# WKUP_CTRL_MMR0_CFG0 register map
Vendor: Texas Instruments
Registers are 32-bit, read-write, reset 0x0 unless marked. A register's access mark holds for its fields unless they carry their own. Offsets are as the file gives them; [hi:lo] are bit positions; {n}, {i} and the like mark numbered series; 'fields as' and 'values as' point back to an identical list.

## WKUP_CTRL_MMR0_CFG0 (part 3 of 11)
{0x6140+4i} CFG0_WKUP_SPARE_STAT{i}_PROXY ro (i=0..3)
  [31:0] WKUP_SPARE_STAT{i}_SPARE_IN_PROXY — Read-only bits. Reset by PORz only. Do not optimize away inputs
{0x6140+4i} CFG0_WKUP_SPARE_STAT{i}_PROXY ro (i=4..7)
  [31:0] WKUP_SPARE_STAT{i}_SPARE_IN_PROXY — Read-only bits. Reset by any reset. Do not optimize away inputs
{0x7100+4i} CFG0_CLAIMREG_P1_R{i} (i=0..2)
  [31:0] CLAIMREG_P1_R{i} — Claim bits for Partition 1
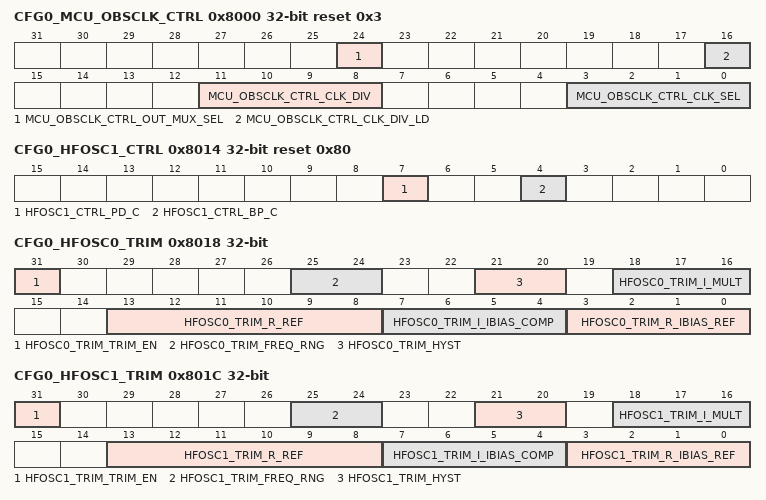
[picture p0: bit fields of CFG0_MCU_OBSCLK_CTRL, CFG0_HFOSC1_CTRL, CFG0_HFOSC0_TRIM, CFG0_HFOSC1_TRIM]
0x8000 CFG0_MCU_OBSCLK_CTRL reset 0x3
  [24] MCU_OBSCLK_CTRL_OUT_MUX_SEL — MCU_OBSCLK pin output mux selection. Note, when HFOSC0_CLK is selected (1'b1) the MCU_OBSCLK_CTRL_clk_sel field must be programmed to 4'b0001. 1'b0 - The output of the MCU_OBSCLK output divider is output on the pin 1'b1 - HFOSC0_CLK is output on the pin
  [16] MCU_OBSCLK_CTRL_CLK_DIV_LD — Load the output divider value Writing 1 to this bit will generate a load pulse to load the OBSCLK divider value. This bit can be cleared but must not be set in the same write cycle in which the clk_div value is changed.
  [11:8] MCU_OBSCLK_CTRL_CLK_DIV — MCU_OBSCLK pin clock selection output divider Output clock is divided by clk_div+1
  [3:0] MCU_OBSCLK_CTRL_CLK_SEL — MCU_OBSCLK pin clock selection Field values (others are reserved): 4'b0000 - CLK_12M_RC 4'b0001 - '0' 4'b0010 - MCU_PLL0_HSDIV0_CLKOUT 4'b0011 - MCU_PLLCTL_OBSCLK 4'b0100 - MCU_PLL1_HSDIV1_CLKOUT 4'b0101 - MCU_PLL1_HSDIV2_CLKOUT 4'b0110 - MCU_PLL1_HSDIV3_CLKOUT 4'b0111 - MCU_PLL1_HSDIV4_CLKOUT 4'b1000 - MCU_PLL2_HSDIV0_CLKOUT 4'b1001 - CLK_32K 4'b1010 - MCU_PLL2_HSDIV1_CLKOUT 4'b1011 - MCU_PLL2_HSDIV2_CLKOUT 4'b1100 - MCU_PLL2_HSDIV3_CLKOUT 4'b1101 - MCU_PLL2_HSDIV4_CLKOUT 4'b1110 - HFOSC0_CLKOUT 4'b1111 - LFXOSC_CLKOUT
0x8014 CFG0_HFOSC1_CTRL reset 0x80
  [7] HFOSC1_CTRL_PD_C — Oscillator powerdown control. When set, oscillator is disabled. Oscillator output is tristated if bp_c=0
  [4] HFOSC1_CTRL_BP_C — Oscillator bypass control. When set oscillator is in bypass mode
0x8018 CFG0_HFOSC0_TRIM
  [31] HFOSC0_TRIM_TRIM_EN — Apply MMR values to OSC trim inputs instead of tie-offs
  [25:24] HFOSC0_TRIM_FREQ_RNG — Sets the frequency range of operation based on: I(MIRRBIAS) = I(AGC) + 4x I(BIAS) (I(BIAS) : Bias current to AMP_AGC Block, I(AGC) : Current from AGC Loop and mirrored)
  [21:20] HFOSC0_TRIM_HYST — Sets comparator hysteresis
  [18:16] HFOSC0_TRIM_I_MULT — AGC AMP current multiplication gain I(MIRRBIAS) = I(AGC) + 4x I(BIAS) (I(BIAS) : Bias current to AMP_AGC Block, I(AGC) : Current from AGC Loop and mirrored)
  [13:8] HFOSC0_TRIM_R_REF — Sets the AMP AGC bias current r_ref(5:3) are not used.
  [7:4] HFOSC0_TRIM_I_IBIAS_COMP — Sets the COMP bias current x = 1 uA
  [3:0] HFOSC0_TRIM_R_IBIAS_REF — Sets the base IBIAS reference
0x801C CFG0_HFOSC1_TRIM
  [31] HFOSC1_TRIM_TRIM_EN — Apply MMR values to OSC trim inputs instead of tie-offs
  [25:24] HFOSC1_TRIM_FREQ_RNG — Sets the frequency range of operation based on: I(MIRRBIAS) = I(AGC) + 4x I(BIAS) (I(BIAS) : Bias current to AMP_AGC Block, I(AGC) : Current from AGC Loop and mirrored)
  [21:20] HFOSC1_TRIM_HYST — Sets comparator hysteresis
  [18:16] HFOSC1_TRIM_I_MULT — AGC AMP current multiplication gain I(MIRRBIAS) = I(AGC) + 4x I(BIAS) (I(BIAS) : Bias current to AMP_AGC Block, I(AGC) : Current from AGC Loop and mirrored)
  [13:8] HFOSC1_TRIM_R_REF — Sets the AMP AGC bias current r_ref(5:3) are not used.
  [7:4] HFOSC1_TRIM_I_IBIAS_COMP — Sets the COMP bias current x = 1 uA
  [3:0] HFOSC1_TRIM_R_IBIAS_REF — Sets the base IBIAS reference
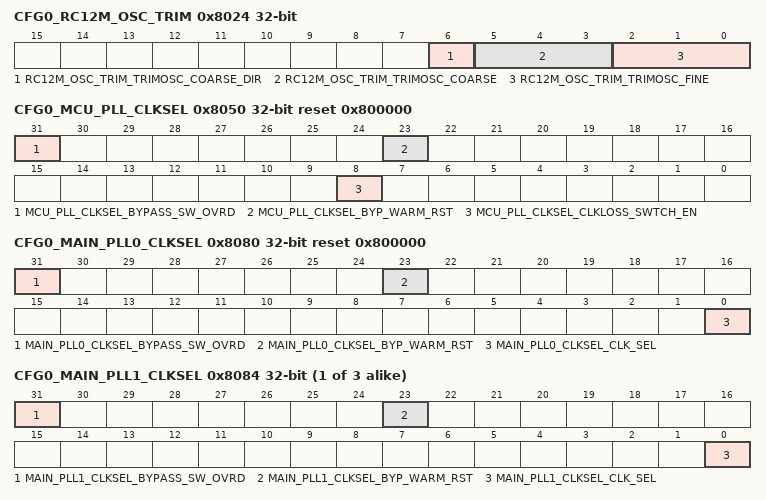
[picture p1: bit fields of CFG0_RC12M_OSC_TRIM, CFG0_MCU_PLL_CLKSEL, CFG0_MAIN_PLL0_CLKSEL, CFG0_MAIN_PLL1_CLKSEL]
0x8024 CFG0_RC12M_OSC_TRIM
  [6] RC12M_OSC_TRIM_TRIMOSC_COARSE_DIR — Coarse adjustment direction. If output is greater than 12.5 0 - Coarse adjustment decreases frequency 1 - Coarse adjustment increases frequency
  [5:3] RC12M_OSC_TRIM_TRIMOSC_COARSE — Coarse adjustment. Frequency is decreased or increased by 1.25 MHz per value based on the trimosc_coarse_dir value.
  [2:0] RC12M_OSC_TRIM_TRIMOSC_FINE — Fine adjustment. Decreases the frequency by 250 KHz per value.
0x8050 CFG0_MCU_PLL_CLKSEL reset 0x800000
  [31] MCU_PLL_CLKSEL_BYPASS_SW_OVRD — PLL Bypass warm reset software override When set, enables software control of exit from bypass mode on a mcu_reset_z for MCU PLL[2:0]. This bit must not be set until after the corresponding byp_warm_rst bit has been cleared or the PLL will immediately enter bypass mode.
  [23] MCU_PLL_CLKSEL_BYP_WARM_RST — PLL bypass mode after warm reset. This bit is only valid when bypass_sw_ovrd is set to 1'b1 to enable bypass software override. This bit is set (1'b1) when an MCU warm reset occurs and will keep MCU PLL[2:0] in bypass mode after reset exit until cleared by software. 1'b0 = Exit bypass mode (based on MCU PLL[2:0]_CTRL_bypass_en bit value) 1'b1 = Maintain bypass mode.
  [8] MCU_PLL_CLKSEL_CLKLOSS_SWTCH_EN — When set, enables automatic switching of MCU PLL[2:0] clock source to CLK_12M_RC if HFOSC0 clock loss is detected
0x8060 CFG0_WKUP_PER_CLKSEL
  [0] WKUP_PER_CLKSEL_MCUPLL_BYPASS — Select the main oscillator clock rather than the PLL generated clock as the functional clock (PLL BYPASS mode). 1'b0: WKUP_I2C functional clock is MCU_PLL1_HSDIV3_CLKOUT WKUP_USART functional clock is MCU_PLL1_HSDIV3_CLKOUT or MAIN_PLL_HSDIV5_CLKOUT as selected by WKUP_USART_CLKSEL.clk_sel 1'b1: WKUP_I2C functional clock is HFOSC0_CLKOUT WKUP_USART functional clock is HFOSC0_CLKOUT
0x8064 CFG0_WKUP_USART_CLKSEL
  [0] WKUP_USART_CLKSEL_CLK_SEL — WKUP_USART0 FCLK selection 1'b0 - MCU_PLL1_HSDIV3_CLKOUT 1'b1 - MAIN_PLL_HSDIV5_CLKOUT
0x8070 CFG0_WKUP_GPIO_CLKSEL
  [1:0] WKUP_GPIO_CLKSEL_WAKE_CLK_SEL — WKUP_GPIO clock selection. Must be set to MCU_SYSCLK0/4 whenever WKUP_GPIO VBUS interface is enabled. Other clock source may be selected as a wake up clock for DeepSleep modes after WKUP_GPIO is gated off through LPSC. Field values (others are reserved): 2'b00 - MCU_SYSCLK0 / 8 2'b01 - MCU_SYSCLK0 / 8 2'b10 - CLK_32K 2'b11 - CLK_12M_RC
0x8080 CFG0_MAIN_PLL0_CLKSEL reset 0x800000
  [31] MAIN_PLL0_CLKSEL_BYPASS_SW_OVRD — PLL Bypass warm reset software override When set, enables software control of exit from bypass mode on a main_reset_z for MAIN PLL0. This bit must not be set until after the corresponding byp_warm_rst bit has been cleared or the PLL will immediately enter bypass mode.
  [23] MAIN_PLL0_CLKSEL_BYP_WARM_RST — PLL bypass mode after warm reset. This bit is only valid when bypass_sw_ovrd is set to 1'b1 to enable bypass software override. This bit is set (1'b1) when a MAIN warm reset occurs and will keep MAIN PLL0 in bypass mode after reset exit until cleared by software. 1'b0 = Exit bypass mode (based on MAIN PLL0_CTRL_bypass_en bit value) 1'b1 = Maintain bypass mode.
  [0] MAIN_PLL0_CLKSEL_CLK_SEL — Selects the clock source for MAIN PLL0 1'b0 - Use HFOSC0_CLKOUT 1'b1 - Use HFOSC1_CLKOUT
{0x8080+4i} CFG0_MAIN_PLL{i}_CLKSEL (i=1..3)
  [31] MAIN_PLL{i}_CLKSEL_BYPASS_SW_OVRD — PLL Bypass warm reset software override This bit has no effect on PLL operation as MAIN PLL{i} is reset isolated and exit from bypass mode (in the case of a Thermal reset) is always hardware controlled.
  [23] MAIN_PLL{i}_CLKSEL_BYP_WARM_RST — PLL bypass mode after warm reset. This bit is cleared to 1'b0 when a MAIN warm reset occurs which will cause MAIN PLL{i} to exit bypass mode after reset exit. Setting this bit will have no effect on PLL behavior. Because MAIN PLL{i} is warm reset insensitive, bypass mode will only be entered (and exited) in the case of a Thermal reset event.
  [0] MAIN_PLL{i}_CLKSEL_CLK_SEL — Selects the clock source for MAIN PLL{i} 1'b0 - Use HFOSC0_CLKOUT 1'b1 - Use HFOSC1_CLKOUT
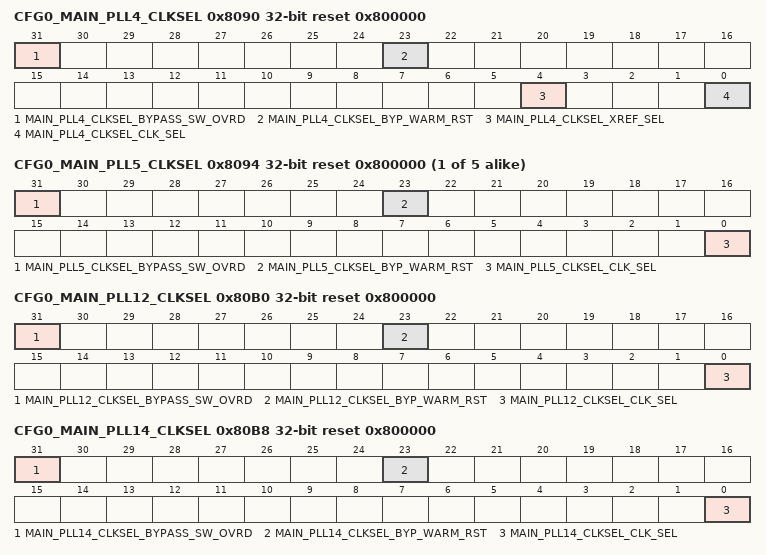
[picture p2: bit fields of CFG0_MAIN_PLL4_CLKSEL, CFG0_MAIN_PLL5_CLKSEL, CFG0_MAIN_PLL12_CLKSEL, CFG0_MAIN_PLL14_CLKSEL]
0x8090 CFG0_MAIN_PLL4_CLKSEL reset 0x800000
  [31] MAIN_PLL4_CLKSEL_BYPASS_SW_OVRD — PLL Bypass warm reset software override When set, enables software control of exit from bypass mode on a main_reset_z for MAIN PLL4. This bit must not be set until after the corresponding byp_warm_rst bit has been cleared or the PLL will immediately enter bypass mode.
  [23] MAIN_PLL4_CLKSEL_BYP_WARM_RST — PLL bypass mode after warm reset. This bit is only valid when bypass_sw_ovrd is set to 1'b1 to enable bypass software override. This bit is set (1'b1) when a MAIN warm reset occurs and will keep MAIN PLL4 in bypass mode after reset exit until cleared by software. 1'b0 = Exit bypass mode (based on MAIN PLL4_CTRL_bypass_en bit value) 1'b1 = Maintain bypass mode.
  [4] MAIN_PLL4_CLKSEL_XREF_SEL — Selects the alternate clock source for MAIN PLL4 1'b0 - Use HFOSC0_CLKOUT or HFOSC1 CLKOUT as selected by clk_sel bit 1'b1 - Use EXT_REFCLK1
  [0] MAIN_PLL4_CLKSEL_CLK_SEL — Selects the clock source for MAIN PLL4 1'b0 - Use HFOSC0_CLKOUT 1'b1 - Use HFOSC1_CLKOUT
{0x8080+4i} CFG0_MAIN_PLL{i}_CLKSEL reset 0x800000 (i=5..9)
  [31] MAIN_PLL{i}_CLKSEL_BYPASS_SW_OVRD — PLL Bypass warm reset software override When set, enables software control of exit from bypass mode on a main_reset_z for MAIN PLL{i}. This bit must not be set until after the corresponding byp_warm_rst bit has been cleared or the PLL will immediately enter bypass mode.
  [23] MAIN_PLL{i}_CLKSEL_BYP_WARM_RST — PLL bypass mode after warm reset. This bit is only valid when bypass_sw_ovrd is set to 1'b1 to enable bypass software override. This bit is set (1'b1) when a MAIN warm reset occurs and will keep MAIN PLL{i} in bypass mode after reset exit until cleared by software. 1'b0 = Exit bypass mode (based on MAIN PLL{i}_CTRL_bypass_en bit value) 1'b1 = Maintain bypass mode.
  [0] MAIN_PLL{i}_CLKSEL_CLK_SEL — Selects the clock source for MAIN PLL{i} 1'b0 - Use HFOSC0_CLKOUT 1'b1 - Use HFOSC1_CLKOUT
0x80B0 CFG0_MAIN_PLL12_CLKSEL reset 0x800000
  [31] MAIN_PLL12_CLKSEL_BYPASS_SW_OVRD — PLL Bypass warm reset software override When set, enables software control of exit from bypass mode on a main_reset_z for MAIN PLL12. This bit must not be set until after the corresponding byp_warm_rst bit has been cleared or the PLL will immediately enter bypass mode.
  [23] MAIN_PLL12_CLKSEL_BYP_WARM_RST — PLL bypass mode after warm reset. This bit is only valid when bypass_sw_ovrd is set to 1'b1 to enable bypass software override. This bit is set (1'b1) when a MAIN warm reset occurs and will keep MAIN PLL12 in bypass mode after reset exit until cleared by software. 1'b0 = Exit bypass mode (based on MAIN PLL12_CTRL_bypass_en bit value) 1'b1 = Maintain bypass mode.
  [0] MAIN_PLL12_CLKSEL_CLK_SEL — Selects the clock source for MAIN PLL12 1'b0 - Use HFOSC0_CLKOUT 1'b1 - Use HFOSC1_CLKOUT
0x80B8 CFG0_MAIN_PLL14_CLKSEL reset 0x800000
  [31] MAIN_PLL14_CLKSEL_BYPASS_SW_OVRD — PLL Bypass warm reset software override When set, enables software control of exit from bypass mode on a main_reset_z for MAIN PLL14. This bit must not be set until after the corresponding byp_warm_rst bit has been cleared or the PLL will immediately enter bypass mode.
  [23] MAIN_PLL14_CLKSEL_BYP_WARM_RST — PLL bypass mode after warm reset. This bit is only valid when bypass_sw_ovrd is set to 1'b1 to enable bypass software override. This bit is set (1'b1) when a MAIN warm reset occurs and will keep MAIN PLL14 in bypass mode after reset exit until cleared by software. 1'b0 = Exit bypass mode (based on MAIN PLL14_CTRL_bypass_en bit value) 1'b1 = Maintain bypass mode.
  [0] MAIN_PLL14_CLKSEL_CLK_SEL — Selects the clock source for MAIN PLL14 1'b0 - Use HFOSC0_CLKOUT 1'b1 - Use HFOSC1_CLKOUT
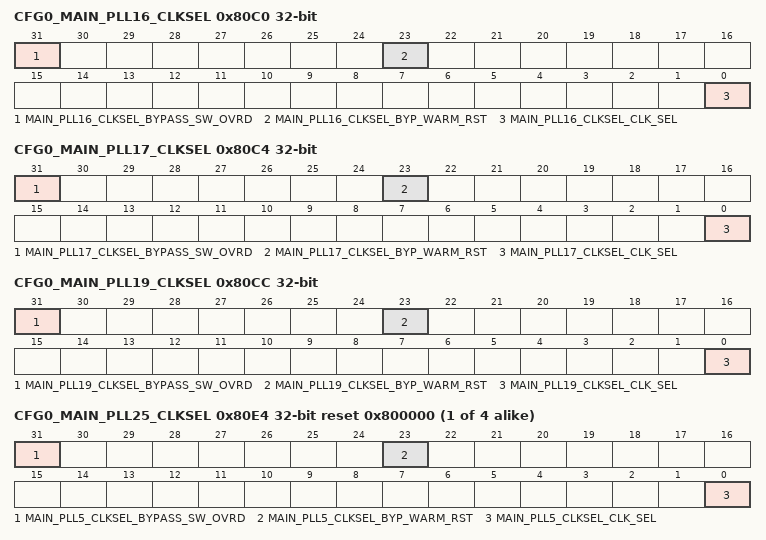
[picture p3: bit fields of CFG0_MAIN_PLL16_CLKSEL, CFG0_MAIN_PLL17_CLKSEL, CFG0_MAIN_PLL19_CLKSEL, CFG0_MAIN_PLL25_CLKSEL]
0x80C0 CFG0_MAIN_PLL16_CLKSEL
  [31] MAIN_PLL16_CLKSEL_BYPASS_SW_OVRD — PLL Bypass warm reset software override This bit has no effect on PLL operation as MAIN PLL16 is reset isolated and exit from bypass mode (in the case of a Thermal reset) is always hardware controlled.
  [23] MAIN_PLL16_CLKSEL_BYP_WARM_RST — PLL bypass mode after warm reset. This bit is cleared to 1'b0 when a MAIN warm reset occurs which will cause MAIN PLL16 to exit bypass mode after reset exit. Setting this bit will have no effect on PLL behavior. Because MAIN PLL16 is warm reset insensitive, bypass mode will only be entered (and exited) in the case of a Thermal reset event.
  [0] MAIN_PLL16_CLKSEL_CLK_SEL — Selects the clock source for MAIN PLL16 1'b0 - Use HFOSC0_CLKOUT 1'b1 - Use HFOSC1_CLKOUT
0x80C4 CFG0_MAIN_PLL17_CLKSEL
  [31] MAIN_PLL17_CLKSEL_BYPASS_SW_OVRD — PLL Bypass warm reset software override This bit has no effect on PLL operation as MAIN PLL17 is reset isolated and exit from bypass mode (in the case of a Thermal reset) is always hardware controlled.
  [23] MAIN_PLL17_CLKSEL_BYP_WARM_RST — PLL bypass mode after warm reset. This bit is cleared to 1'b0 when a MAIN warm reset occurs which will cause MAIN PLL17 to exit bypass mode after reset exit. Setting this bit will have no effect on PLL behavior. Because MAIN PLL17 is warm reset insensitive, bypass mode will only be entered (and exited) in the case of a Thermal reset event.
  [0] MAIN_PLL17_CLKSEL_CLK_SEL — Selects the clock source for MAIN PLL17 1'b0 - Use HFOSC0_CLKOUT 1'b1 - Use HFOSC1_CLKOUT
0x80CC CFG0_MAIN_PLL19_CLKSEL
  [31] MAIN_PLL19_CLKSEL_BYPASS_SW_OVRD — PLL Bypass warm reset software override This bit has no effect on PLL operation as MAIN PLL19 is reset isolated and exit from bypass mode (in the case of a Thermal reset) is always hardware controlled.
  [23] MAIN_PLL19_CLKSEL_BYP_WARM_RST — PLL bypass mode after warm reset. This bit is cleared to 1'b0 when a MAIN warm reset occurs which will cause MAIN PLL19 to exit bypass mode after reset exit. Setting this bit will have no effect on PLL behavior. Because MAIN PLL19 is warm reset insensitive, bypass mode will only be entered (and exited) in the case of a Thermal reset event.
  [0] MAIN_PLL19_CLKSEL_CLK_SEL — Selects the clock source for MAIN PLL19 1'b0 - Use HFOSC0_CLKOUT 1'b1 - Use HFOSC1_CLKOUT
{0x8080+4i} CFG0_MAIN_PLL{i}_CLKSEL reset 0x800000 (i=25..28)
  fields as CFG0_MAIN_PLL5_CLKSEL
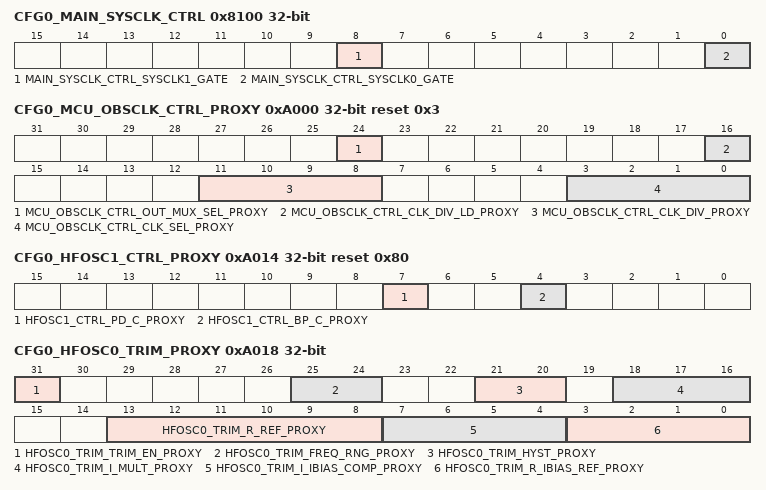
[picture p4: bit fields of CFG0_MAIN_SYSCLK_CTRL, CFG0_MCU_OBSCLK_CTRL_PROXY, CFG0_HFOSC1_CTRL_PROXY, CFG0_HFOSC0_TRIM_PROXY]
0x8100 CFG0_MAIN_SYSCLK_CTRL
  [8] MAIN_SYSCLK_CTRL_SYSCLK1_GATE — When set, gates off SYSCLK1 output of the MAIN PLL Controller
  [0] MAIN_SYSCLK_CTRL_SYSCLK0_GATE — When set, gates off SYSCLK0 (MCLK1) output of the MAIN PLL Controller
0x8110 CFG0_MCU_SPI0_CLKSEL
  [16] MCU_SPI0_CLKSEL_MSTR_LB_CLKSEL — Master mode receive capture clock loopback selection 1'b0 - Internal clock loopback 1'b1 - Loopback from pad
0x8114 CFG0_MCU_SPI1_CLKSEL
  [16] MCU_SPI1_CLKSEL_MSTR_LB_CLKSEL — Master mode receive capture clock loopback selection 1'b0 - Internal clock loopback 1'b1 - Loopback from pad
{0x9100+4i} CFG0_CLAIMREG_P2_R{i}_READONLY ro (i=0..2)
  [31:0] CLAIMREG_P2_R{i}_READONLY — Claim bits for Partition 2
0xA000 CFG0_MCU_OBSCLK_CTRL_PROXY reset 0x3
  [24] MCU_OBSCLK_CTRL_OUT_MUX_SEL_PROXY — MCU_OBSCLK pin output mux selection. Note, when HFOSC0_CLK is selected (1'b1) the MCU_OBSCLK_CTRL_clk_sel field must be programmed to 4'b0001. 1'b0 - The output of the MCU_OBSCLK output divider is output on the pin 1'b1 - HFOSC0_CLK is output on the pin
  [16] MCU_OBSCLK_CTRL_CLK_DIV_LD_PROXY — Load the output divider value Writing 1 to this bit will generate a load pulse to load the OBSCLK divider value. This bit can be cleared but must not be set in the same write cycle in which the clk_div value is changed.
  [11:8] MCU_OBSCLK_CTRL_CLK_DIV_PROXY — MCU_OBSCLK pin clock selection output divider Output clock is divided by clk_div+1
  [3:0] MCU_OBSCLK_CTRL_CLK_SEL_PROXY — MCU_OBSCLK pin clock selection Field values (others are reserved): 4'b0000 - CLK_12M_RC 4'b0001 - '0' 4'b0010 - MCU_PLL0_HSDIV0_CLKOUT 4'b0011 - MCU_PLLCTL_OBSCLK 4'b0100 - MCU_PLL1_HSDIV1_CLKOUT 4'b0101 - MCU_PLL1_HSDIV2_CLKOUT 4'b0110 - MCU_PLL1_HSDIV3_CLKOUT 4'b0111 - MCU_PLL1_HSDIV4_CLKOUT 4'b1000 - MCU_PLL2_HSDIV0_CLKOUT 4'b1001 - CLK_32K 4'b1010 - MCU_PLL2_HSDIV1_CLKOUT 4'b1011 - MCU_PLL2_HSDIV2_CLKOUT 4'b1100 - MCU_PLL2_HSDIV3_CLKOUT 4'b1101 - MCU_PLL2_HSDIV4_CLKOUT 4'b1110 - HFOSC0_CLKOUT 4'b1111 - LFXOSC_CLKOUT
0xA014 CFG0_HFOSC1_CTRL_PROXY reset 0x80
  [7] HFOSC1_CTRL_PD_C_PROXY — Oscillator powerdown control. When set, oscillator is disabled. Oscillator output is tristated if bp_c=0
  [4] HFOSC1_CTRL_BP_C_PROXY — Oscillator bypass control. When set oscillator is in bypass mode
0xA018 CFG0_HFOSC0_TRIM_PROXY
  [31] HFOSC0_TRIM_TRIM_EN_PROXY — Apply MMR values to OSC trim inputs instead of tie-offs
  [25:24] HFOSC0_TRIM_FREQ_RNG_PROXY — Sets the frequency range of operation based on: I(MIRRBIAS) = I(AGC) + 4x I(BIAS) (I(BIAS) : Bias current to AMP_AGC Block, I(AGC) : Current from AGC Loop and mirrored)
  [21:20] HFOSC0_TRIM_HYST_PROXY — Sets comparator hysteresis
  [18:16] HFOSC0_TRIM_I_MULT_PROXY — AGC AMP current multiplication gain I(MIRRBIAS) = I(AGC) + 4x I(BIAS) (I(BIAS) : Bias current to AMP_AGC Block, I(AGC) : Current from AGC Loop and mirrored)
  [13:8] HFOSC0_TRIM_R_REF_PROXY — Sets the AMP AGC bias current r_ref(5:3) are not used.
  [7:4] HFOSC0_TRIM_I_IBIAS_COMP_PROXY — Sets the COMP bias current x = 1 uA
  [3:0] HFOSC0_TRIM_R_IBIAS_REF_PROXY — Sets the base IBIAS reference
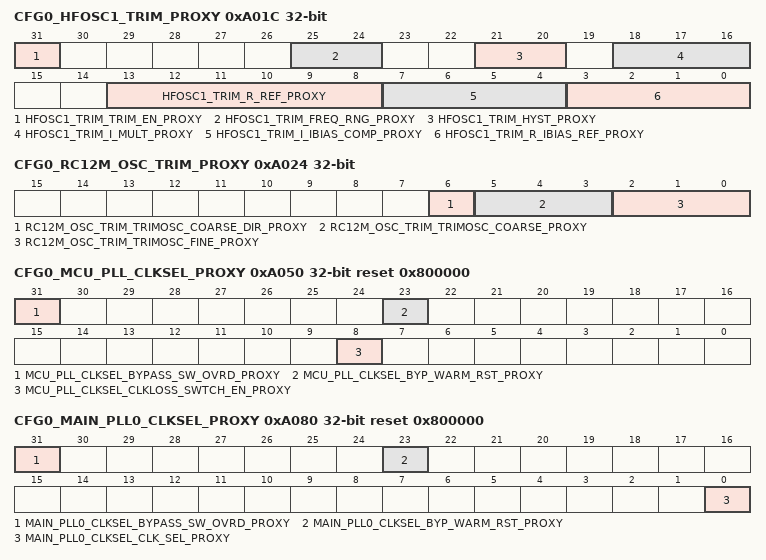
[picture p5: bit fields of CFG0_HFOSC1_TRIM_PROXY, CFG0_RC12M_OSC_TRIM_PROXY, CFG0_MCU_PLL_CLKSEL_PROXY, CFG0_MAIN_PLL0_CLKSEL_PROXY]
0xA01C CFG0_HFOSC1_TRIM_PROXY
  [31] HFOSC1_TRIM_TRIM_EN_PROXY — Apply MMR values to OSC trim inputs instead of tie-offs
  [25:24] HFOSC1_TRIM_FREQ_RNG_PROXY — Sets the frequency range of operation based on: I(MIRRBIAS) = I(AGC) + 4x I(BIAS) (I(BIAS) : Bias current to AMP_AGC Block, I(AGC) : Current from AGC Loop and mirrored)
  [21:20] HFOSC1_TRIM_HYST_PROXY — Sets comparator hysteresis
  [18:16] HFOSC1_TRIM_I_MULT_PROXY — AGC AMP current multiplication gain I(MIRRBIAS) = I(AGC) + 4x I(BIAS) (I(BIAS) : Bias current to AMP_AGC Block, I(AGC) : Current from AGC Loop and mirrored)
  [13:8] HFOSC1_TRIM_R_REF_PROXY — Sets the AMP AGC bias current r_ref(5:3) are not used.
  [7:4] HFOSC1_TRIM_I_IBIAS_COMP_PROXY — Sets the COMP bias current x = 1 uA
  [3:0] HFOSC1_TRIM_R_IBIAS_REF_PROXY — Sets the base IBIAS reference
0xA024 CFG0_RC12M_OSC_TRIM_PROXY
  [6] RC12M_OSC_TRIM_TRIMOSC_COARSE_DIR_PROXY — Coarse adjustment direction. If output is greater than 12.5 0 - Coarse adjustment decreases frequency 1 - Coarse adjustment increases frequency
  [5:3] RC12M_OSC_TRIM_TRIMOSC_COARSE_PROXY — Coarse adjustment. Frequency is decreased or increased by 1.25 MHz per value based on the trimosc_coarse_dir value.
  [2:0] RC12M_OSC_TRIM_TRIMOSC_FINE_PROXY — Fine adjustment. Decreases the frequency by 250 KHz per value.
0xA050 CFG0_MCU_PLL_CLKSEL_PROXY reset 0x800000
  [31] MCU_PLL_CLKSEL_BYPASS_SW_OVRD_PROXY — PLL Bypass warm reset software override When set, enables software control of exit from bypass mode on a mcu_reset_z for MCU PLL[2:0]. This bit must not be set until after the corresponding byp_warm_rst bit has been cleared or the PLL will immediately enter bypass mode.
  [23] MCU_PLL_CLKSEL_BYP_WARM_RST_PROXY — PLL bypass mode after warm reset. This bit is only valid when bypass_sw_ovrd is set to 1'b1 to enable bypass software override. This bit is set (1'b1) when an MCU warm reset occurs and will keep MCU PLL[2:0] in bypass mode after reset exit until cleared by software. 1'b0 = Exit bypass mode (based on MCU PLL[2:0]_CTRL_bypass_en bit value) 1'b1 = Maintain bypass mode.
  [8] MCU_PLL_CLKSEL_CLKLOSS_SWTCH_EN_PROXY — When set, enables automatic switching of MCU PLL[2:0] clock source to CLK_12M_RC if HFOSC0 clock loss is detected
0xA060 CFG0_WKUP_PER_CLKSEL_PROXY
  [0] WKUP_PER_CLKSEL_MCUPLL_BYPASS_PROXY — Select the main oscillator clock rather than the PLL generated clock as the functional clock (PLL BYPASS mode). 1'b0: WKUP_I2C functional clock is MCU_PLL1_HSDIV3_CLKOUT WKUP_USART functional clock is MCU_PLL1_HSDIV3_CLKOUT or MAIN_PLL_HSDIV5_CLKOUT as selected by WKUP_USART_CLKSEL.clk_sel 1'b1: WKUP_I2C functional clock is HFOSC0_CLKOUT WKUP_USART functional clock is HFOSC0_CLKOUT
0xA064 CFG0_WKUP_USART_CLKSEL_PROXY
  [0] WKUP_USART_CLKSEL_CLK_SEL_PROXY — WKUP_USART0 FCLK selection 1'b0 - MCU_PLL1_HSDIV3_CLKOUT 1'b1 - MAIN_PLL_HSDIV5_CLKOUT
0xA070 CFG0_WKUP_GPIO_CLKSEL_PROXY
  [1:0] WKUP_GPIO_CLKSEL_WAKE_CLK_SEL_PROXY — WKUP_GPIO clock selection. Must be set to MCU_SYSCLK0/4 whenever WKUP_GPIO VBUS interface is enabled. Other clock source may be selected as a wake up clock for DeepSleep modes after WKUP_GPIO is gated off through LPSC. Field values (others are reserved): 2'b00 - MCU_SYSCLK0 / 8 2'b01 - MCU_SYSCLK0 / 8 2'b10 - CLK_32K 2'b11 - CLK_12M_RC
0xA080 CFG0_MAIN_PLL0_CLKSEL_PROXY reset 0x800000
  [31] MAIN_PLL0_CLKSEL_BYPASS_SW_OVRD_PROXY — PLL Bypass warm reset software override When set, enables software control of exit from bypass mode on a main_reset_z for MAIN PLL0. This bit must not be set until after the corresponding byp_warm_rst bit has been cleared or the PLL will immediately enter bypass mode.
  [23] MAIN_PLL0_CLKSEL_BYP_WARM_RST_PROXY — PLL bypass mode after warm reset. This bit is only valid when bypass_sw_ovrd is set to 1'b1 to enable bypass software override. This bit is set (1'b1) when a MAIN warm reset occurs and will keep MAIN PLL0 in bypass mode after reset exit until cleared by software. 1'b0 = Exit bypass mode (based on MAIN PLL0_CTRL_bypass_en bit value) 1'b1 = Maintain bypass mode.
  [0] MAIN_PLL0_CLKSEL_CLK_SEL_PROXY — Selects the clock source for MAIN PLL0 1'b0 - Use HFOSC0_CLKOUT 1'b1 - Use HFOSC1_CLKOUT
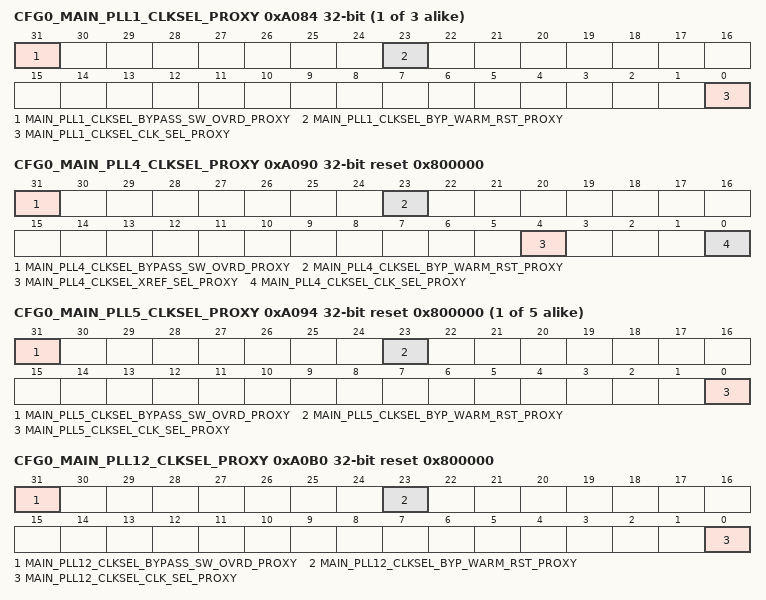
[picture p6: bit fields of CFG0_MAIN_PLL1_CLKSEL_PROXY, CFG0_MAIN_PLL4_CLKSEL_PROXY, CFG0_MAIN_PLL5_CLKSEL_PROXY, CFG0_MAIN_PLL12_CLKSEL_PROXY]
{0xA080+4i} CFG0_MAIN_PLL{i}_CLKSEL_PROXY (i=1..3)
  [31] MAIN_PLL{i}_CLKSEL_BYPASS_SW_OVRD_PROXY — PLL Bypass warm reset software override This bit has no effect on PLL operation as MAIN PLL{i} is reset isolated and exit from bypass mode (in the case of a Thermal reset) is always hardware controlled.
  [23] MAIN_PLL{i}_CLKSEL_BYP_WARM_RST_PROXY — PLL bypass mode after warm reset. This bit is cleared to 1'b0 when a MAIN warm reset occurs which will cause MAIN PLL{i} to exit bypass mode after reset exit. Setting this bit will have no effect on PLL behavior. Because MAIN PLL{i} is warm reset insensitive, bypass mode will only be entered (and exited) in the case of a Thermal reset event.
  [0] MAIN_PLL{i}_CLKSEL_CLK_SEL_PROXY — Selects the clock source for MAIN PLL{i} 1'b0 - Use HFOSC0_CLKOUT 1'b1 - Use HFOSC1_CLKOUT
0xA090 CFG0_MAIN_PLL4_CLKSEL_PROXY reset 0x800000
  [31] MAIN_PLL4_CLKSEL_BYPASS_SW_OVRD_PROXY — PLL Bypass warm reset software override When set, enables software control of exit from bypass mode on a main_reset_z for MAIN PLL4. This bit must not be set until after the corresponding byp_warm_rst bit has been cleared or the PLL will immediately enter bypass mode.
  [23] MAIN_PLL4_CLKSEL_BYP_WARM_RST_PROXY — PLL bypass mode after warm reset. This bit is only valid when bypass_sw_ovrd is set to 1'b1 to enable bypass software override. This bit is set (1'b1) when a MAIN warm reset occurs and will keep MAIN PLL4 in bypass mode after reset exit until cleared by software. 1'b0 = Exit bypass mode (based on MAIN PLL4_CTRL_bypass_en bit value) 1'b1 = Maintain bypass mode.
  [4] MAIN_PLL4_CLKSEL_XREF_SEL_PROXY — Selects the alternate clock source for MAIN PLL4 1'b0 - Use HFOSC0_CLKOUT or HFOSC1 CLKOUT as selected by clk_sel bit 1'b1 - Use EXT_REFCLK1
  [0] MAIN_PLL4_CLKSEL_CLK_SEL_PROXY — Selects the clock source for MAIN PLL4 1'b0 - Use HFOSC0_CLKOUT 1'b1 - Use HFOSC1_CLKOUT
{0xA080+4i} CFG0_MAIN_PLL{i}_CLKSEL_PROXY reset 0x800000 (i=5..9)
  [31] MAIN_PLL{i}_CLKSEL_BYPASS_SW_OVRD_PROXY — PLL Bypass warm reset software override When set, enables software control of exit from bypass mode on a main_reset_z for MAIN PLL{i}. This bit must not be set until after the corresponding byp_warm_rst bit has been cleared or the PLL will immediately enter bypass mode.
  [23] MAIN_PLL{i}_CLKSEL_BYP_WARM_RST_PROXY — PLL bypass mode after warm reset. This bit is only valid when bypass_sw_ovrd is set to 1'b1 to enable bypass software override. This bit is set (1'b1) when a MAIN warm reset occurs and will keep MAIN PLL{i} in bypass mode after reset exit until cleared by software. 1'b0 = Exit bypass mode (based on MAIN PLL{i}_CTRL_bypass_en bit value) 1'b1 = Maintain bypass mode.
  [0] MAIN_PLL{i}_CLKSEL_CLK_SEL_PROXY — Selects the clock source for MAIN PLL{i} 1'b0 - Use HFOSC0_CLKOUT 1'b1 - Use HFOSC1_CLKOUT
0xA0B0 CFG0_MAIN_PLL12_CLKSEL_PROXY reset 0x800000
  [31] MAIN_PLL12_CLKSEL_BYPASS_SW_OVRD_PROXY — PLL Bypass warm reset software override When set, enables software control of exit from bypass mode on a main_reset_z for MAIN PLL12. This bit must not be set until after the corresponding byp_warm_rst bit has been cleared or the PLL will immediately enter bypass mode.
  [23] MAIN_PLL12_CLKSEL_BYP_WARM_RST_PROXY — PLL bypass mode after warm reset. This bit is only valid when bypass_sw_ovrd is set to 1'b1 to enable bypass software override. This bit is set (1'b1) when a MAIN warm reset occurs and will keep MAIN PLL12 in bypass mode after reset exit until cleared by software. 1'b0 = Exit bypass mode (based on MAIN PLL12_CTRL_bypass_en bit value) 1'b1 = Maintain bypass mode.
  [0] MAIN_PLL12_CLKSEL_CLK_SEL_PROXY — Selects the clock source for MAIN PLL12 1'b0 - Use HFOSC0_CLKOUT 1'b1 - Use HFOSC1_CLKOUT
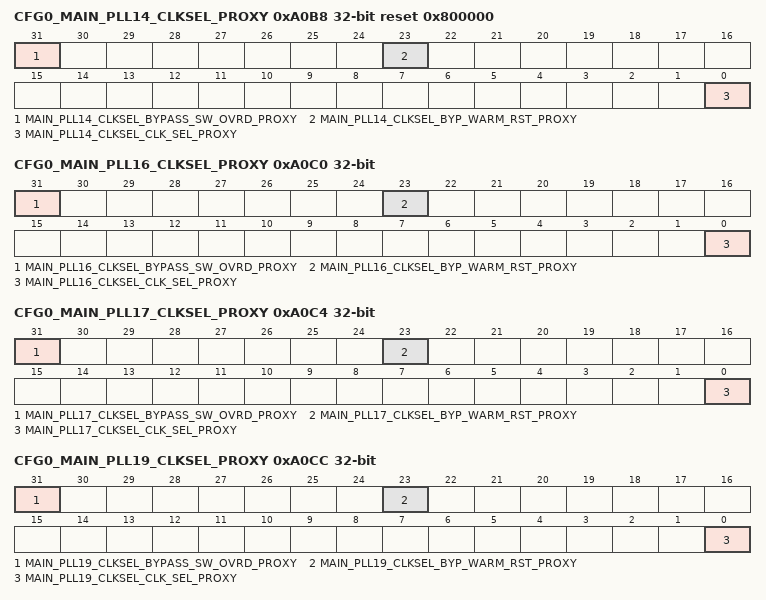
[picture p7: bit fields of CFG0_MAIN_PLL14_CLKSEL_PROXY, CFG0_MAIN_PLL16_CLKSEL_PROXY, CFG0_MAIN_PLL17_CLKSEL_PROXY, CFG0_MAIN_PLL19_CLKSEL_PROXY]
0xA0B8 CFG0_MAIN_PLL14_CLKSEL_PROXY reset 0x800000
  [31] MAIN_PLL14_CLKSEL_BYPASS_SW_OVRD_PROXY — PLL Bypass warm reset software override When set, enables software control of exit from bypass mode on a main_reset_z for MAIN PLL14. This bit must not be set until after the corresponding byp_warm_rst bit has been cleared or the PLL will immediately enter bypass mode.
  [23] MAIN_PLL14_CLKSEL_BYP_WARM_RST_PROXY — PLL bypass mode after warm reset. This bit is only valid when bypass_sw_ovrd is set to 1'b1 to enable bypass software override. This bit is set (1'b1) when a MAIN warm reset occurs and will keep MAIN PLL14 in bypass mode after reset exit until cleared by software. 1'b0 = Exit bypass mode (based on MAIN PLL14_CTRL_bypass_en bit value) 1'b1 = Maintain bypass mode.
  [0] MAIN_PLL14_CLKSEL_CLK_SEL_PROXY — Selects the clock source for MAIN PLL14 1'b0 - Use HFOSC0_CLKOUT 1'b1 - Use HFOSC1_CLKOUT
0xA0C0 CFG0_MAIN_PLL16_CLKSEL_PROXY
  [31] MAIN_PLL16_CLKSEL_BYPASS_SW_OVRD_PROXY — PLL Bypass warm reset software override This bit has no effect on PLL operation as MAIN PLL16 is reset isolated and exit from bypass mode (in the case of a Thermal reset) is always hardware controlled.
  [23] MAIN_PLL16_CLKSEL_BYP_WARM_RST_PROXY — PLL bypass mode after warm reset. This bit is cleared to 1'b0 when a MAIN warm reset occurs which will cause MAIN PLL16 to exit bypass mode after reset exit. Setting this bit will have no effect on PLL behavior. Because MAIN PLL16 is warm reset insensitive, bypass mode will only be entered (and exited) in the case of a Thermal reset event.
  [0] MAIN_PLL16_CLKSEL_CLK_SEL_PROXY — Selects the clock source for MAIN PLL16 1'b0 - Use HFOSC0_CLKOUT 1'b1 - Use HFOSC1_CLKOUT
0xA0C4 CFG0_MAIN_PLL17_CLKSEL_PROXY
  [31] MAIN_PLL17_CLKSEL_BYPASS_SW_OVRD_PROXY — PLL Bypass warm reset software override This bit has no effect on PLL operation as MAIN PLL17 is reset isolated and exit from bypass mode (in the case of a Thermal reset) is always hardware controlled.
  [23] MAIN_PLL17_CLKSEL_BYP_WARM_RST_PROXY — PLL bypass mode after warm reset. This bit is cleared to 1'b0 when a MAIN warm reset occurs which will cause MAIN PLL17 to exit bypass mode after reset exit. Setting this bit will have no effect on PLL behavior. Because MAIN PLL17 is warm reset insensitive, bypass mode will only be entered (and exited) in the case of a Thermal reset event.
  [0] MAIN_PLL17_CLKSEL_CLK_SEL_PROXY — Selects the clock source for MAIN PLL17 1'b0 - Use HFOSC0_CLKOUT 1'b1 - Use HFOSC1_CLKOUT
0xA0CC CFG0_MAIN_PLL19_CLKSEL_PROXY
  [31] MAIN_PLL19_CLKSEL_BYPASS_SW_OVRD_PROXY — PLL Bypass warm reset software override This bit has no effect on PLL operation as MAIN PLL19 is reset isolated and exit from bypass mode (in the case of a Thermal reset) is always hardware controlled.
  [23] MAIN_PLL19_CLKSEL_BYP_WARM_RST_PROXY — PLL bypass mode after warm reset. This bit is cleared to 1'b0 when a MAIN warm reset occurs which will cause MAIN PLL19 to exit bypass mode after reset exit. Setting this bit will have no effect on PLL behavior. Because MAIN PLL19 is warm reset insensitive, bypass mode will only be entered (and exited) in the case of a Thermal reset event.
  [0] MAIN_PLL19_CLKSEL_CLK_SEL_PROXY — Selects the clock source for MAIN PLL19 1'b0 - Use HFOSC0_CLKOUT 1'b1 - Use HFOSC1_CLKOUT
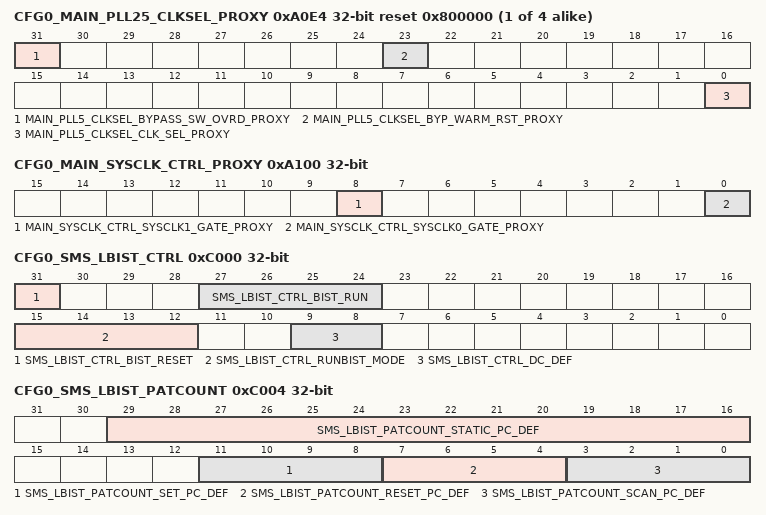
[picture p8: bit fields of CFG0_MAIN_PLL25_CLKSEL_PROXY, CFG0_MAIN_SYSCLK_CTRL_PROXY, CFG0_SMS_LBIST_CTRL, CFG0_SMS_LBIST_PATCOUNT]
{0xA080+4i} CFG0_MAIN_PLL{i}_CLKSEL_PROXY reset 0x800000 (i=25..28)
  fields as CFG0_MAIN_PLL5_CLKSEL_PROXY
0xA100 CFG0_MAIN_SYSCLK_CTRL_PROXY
  [8] MAIN_SYSCLK_CTRL_SYSCLK1_GATE_PROXY — When set, gates off SYSCLK1 output of the MAIN PLL Controller
  [0] MAIN_SYSCLK_CTRL_SYSCLK0_GATE_PROXY — When set, gates off SYSCLK0 (MCLK1) output of the MAIN PLL Controller
0xA110 CFG0_MCU_SPI0_CLKSEL_PROXY
  [16] MCU_SPI0_CLKSEL_MSTR_LB_CLKSEL_PROXY — Master mode receive capture clock loopback selection 1'b0 - Internal clock loopback 1'b1 - Loopback from pad
0xA114 CFG0_MCU_SPI1_CLKSEL_PROXY
  [16] MCU_SPI1_CLKSEL_MSTR_LB_CLKSEL_PROXY — Master mode receive capture clock loopback selection 1'b0 - Internal clock loopback 1'b1 - Loopback from pad
{0xB100+4i} CFG0_CLAIMREG_P2_R{i} (i=0..2)
  [31:0] CLAIMREG_P2_R{i} — Claim bits for Partition 2
0xC000 CFG0_SMS_LBIST_CTRL
  [31] SMS_LBIST_CTRL_BIST_RESET — (Active low) This bitfield is not used. The bist_reset control for SMS is generated by the POST state machine. The bitfield still reflects the efuse value.
  [27:24] SMS_LBIST_CTRL_BIST_RUN — This bitfield is not used. The bist_run control for SMS is generated by the POST state machine. The bitfield still reflects the efuse value.
  [15:12] SMS_LBIST_CTRL_RUNBIST_MODE — Runbist mode enable if all bits are 1
  [9:8] SMS_LBIST_CTRL_DC_DEF — Clock delay after scan_enable switching
0xC004 CFG0_SMS_LBIST_PATCOUNT
  [29:16] SMS_LBIST_PATCOUNT_STATIC_PC_DEF — Number of stuck-at patterns to run
  [11:8] SMS_LBIST_PATCOUNT_SET_PC_DEF — Number of set patterns to run
  [7:4] SMS_LBIST_PATCOUNT_RESET_PC_DEF — Number of reset patterns to run
  [3:0] SMS_LBIST_PATCOUNT_SCAN_PC_DEF — Number of chain test patterns to run
0xC008 CFG0_SMS_LBIST_SEED0
  [31:0] SMS_LBIST_SEED0_PRPG_DEF — Initial seed for PRPG (bits 31:0)
0xC00C CFG0_SMS_LBIST_SEED1
  [20:0] SMS_LBIST_SEED1_PRPG_DEF — Initial seed for PRPG (bits 52:32)
0xC010 CFG0_SMS_LBIST_SPARE0
  [31:0] SMS_LBIST_SPARE0_SPARE0 — LBIST spare bits
0xC014 CFG0_SMS_LBIST_SPARE1
  [31:0] SMS_LBIST_SPARE1_SPARE1 — LBIST spare bits
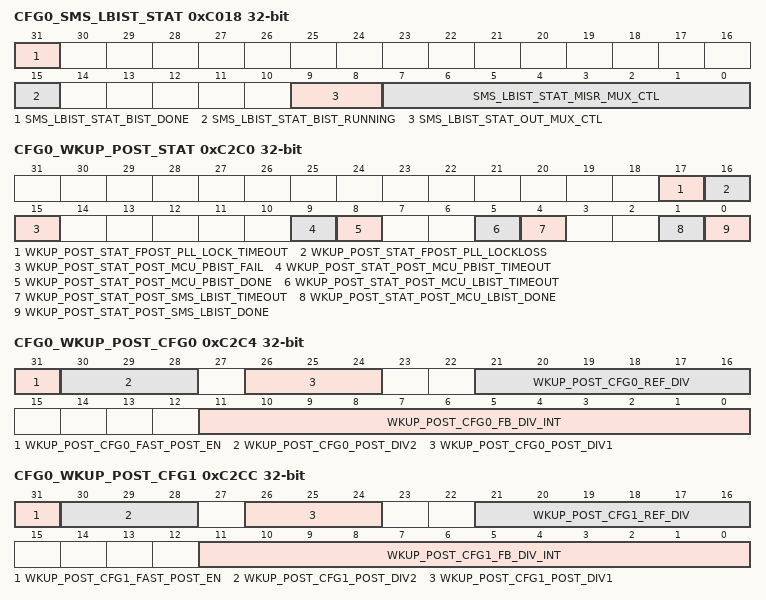
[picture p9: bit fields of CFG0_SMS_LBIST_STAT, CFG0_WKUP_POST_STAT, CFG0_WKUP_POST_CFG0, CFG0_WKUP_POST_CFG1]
0xC018 CFG0_SMS_LBIST_STAT access per field
  [31] SMS_LBIST_STAT_BIST_DONE ro — LBIST is done
  [15] SMS_LBIST_STAT_BIST_RUNNING ro — LBIST is running
  [9:8] SMS_LBIST_STAT_OUT_MUX_CTL rw — Selects source of LBIST output 00 - LBIST IP PID value 01 - LBIST CTRL ID value 1x - MISR value
  [7:0] SMS_LBIST_STAT_MISR_MUX_CTL rw — Selects block of 32 MISR bits to read. A value of 0 selects a compacted 32-bit version of the full MISR. A value of 1-32 select a 32-bit segment of the MISR.
0xC01C CFG0_SMS_LBIST_MISR ro
  [31:0] SMS_LBIST_MISR_MISR_RESULT — 32-bits of MISR value selected by misr_mux_ctl
0xC280 CFG0_SMS_LBIST_SIG ro
  [31:0] SMS_LBIST_SIG_MISR_SIG — MISR signature
0xC2C0 CFG0_WKUP_POST_STAT ro
  [17] WKUP_POST_STAT_FPOST_PLL_LOCK_TIMEOUT — Indicates PLL lock timeout for Fast POST mode operation. 0 - PLLs locked, Fast POST mode was entered 1 - PLLs lock timeout occurred. Slow speed POST was performed
  [16] WKUP_POST_STAT_FPOST_PLL_LOCKLOSS — Indicates if PLL lock was lost during POST 0 - No PLL lock loss. Fast POST was executed 1 - PLL lock was lost. POST was terminated
  [15] WKUP_POST_STAT_POST_MCU_PBIST_FAIL — MCU PBIST failed
  [9] WKUP_POST_STAT_POST_MCU_PBIST_TIMEOUT — MCU PBIST timed out
  [8] WKUP_POST_STAT_POST_MCU_PBIST_DONE — MCU PBIST done
  [5] WKUP_POST_STAT_POST_MCU_LBIST_TIMEOUT — MCU LBIST timed out
  [4] WKUP_POST_STAT_POST_SMS_LBIST_TIMEOUT — SMS LBIST timed out
  [1] WKUP_POST_STAT_POST_MCU_LBIST_DONE — MCU LBIST done
  [0] WKUP_POST_STAT_POST_SMS_LBIST_DONE — SMS LBIST done
0xC2C4 CFG0_WKUP_POST_CFG0 ro
  [31] WKUP_POST_CFG0_FAST_POST_EN — Enable Fast POST mode
  [30:28] WKUP_POST_CFG0_POST_DIV2 — Fast POST PLL secondary post-divider value
  [26:24] WKUP_POST_CFG0_POST_DIV1 — Fast POST PLL primary post-divider value
  [21:16] WKUP_POST_CFG0_REF_DIV — Fast POST PLL reference clock pre-divider value
  [11:0] WKUP_POST_CFG0_FB_DIV_INT — Fast POST PLL feedback divider (integer portion) value
0xC2CC CFG0_WKUP_POST_CFG1 ro
  [31] WKUP_POST_CFG1_FAST_POST_EN — Enable Fast POST mode
  [30:28] WKUP_POST_CFG1_POST_DIV2 — Fast POST PLL secondary post-divider value
  [26:24] WKUP_POST_CFG1_POST_DIV1 — Fast POST PLL primary post-divider value
  [21:16] WKUP_POST_CFG1_REF_DIV — Fast POST PLL reference clock pre-divider value
  [11:0] WKUP_POST_CFG1_FB_DIV_INT — Fast POST PLL feedback divider (integer portion) value
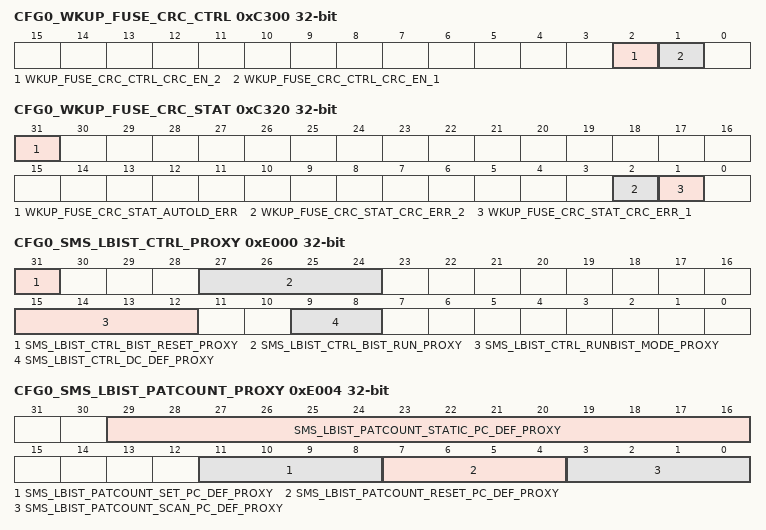
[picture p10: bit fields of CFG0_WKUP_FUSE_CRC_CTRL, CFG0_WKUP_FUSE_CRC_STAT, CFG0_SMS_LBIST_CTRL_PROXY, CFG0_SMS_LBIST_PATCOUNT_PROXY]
0xC300 CFG0_WKUP_FUSE_CRC_CTRL
  [2] WKUP_FUSE_CRC_CTRL_CRC_EN_2 — Enable eFuse CRC error output for chain 2
  [1] WKUP_FUSE_CRC_CTRL_CRC_EN_1 — Enable eFuse CRC error output for chain 1
0xC304 CFG0_WKUP_CHAIN1_CRC_FUSE ro
  [31:0] WKUP_CHAIN1_CRC_FUSE_CRC — Stored chain CRC
0xC308 CFG0_WKUP_CHAIN2_CRC_FUSE ro
  [31:0] WKUP_CHAIN2_CRC_FUSE_CRC — Stored chain CRC
0xC320 CFG0_WKUP_FUSE_CRC_STAT ro
  [31] WKUP_FUSE_CRC_STAT_AUTOLD_ERR — Indicates eFuse autoload or programmation error on any chain
  [2] WKUP_FUSE_CRC_STAT_CRC_ERR_2 — Indicates eFuse CRC error on chain 2
  [1] WKUP_FUSE_CRC_STAT_CRC_ERR_1 — Indicates eFuse CRC error on chain 1
0xC324 CFG0_WKUP_CHAIN1_CRC_CALC ro
  [31:0] WKUP_CHAIN1_CRC_CALC_CRC — Calculated chain CRC
0xC328 CFG0_WKUP_CHAIN2_CRC_CALC ro
  [31:0] WKUP_CHAIN2_CRC_CALC_CRC — Calculated chain CRC
{0xD100+4i} CFG0_CLAIMREG_P3_R{i}_READONLY ro (i=0..6)
  [31:0] CLAIMREG_P3_R{i}_READONLY — Claim bits for Partition 3
0xE000 CFG0_SMS_LBIST_CTRL_PROXY
  [31] SMS_LBIST_CTRL_BIST_RESET_PROXY — (Active low) This bitfield is not used. The bist_reset control for SMS is generated by the POST state machine. The bitfield still reflects the efuse value.
  [27:24] SMS_LBIST_CTRL_BIST_RUN_PROXY — This bitfield is not used. The bist_run control for SMS is generated by the POST state machine. The bitfield still reflects the efuse value.
  [15:12] SMS_LBIST_CTRL_RUNBIST_MODE_PROXY — Runbist mode enable if all bits are 1
  [9:8] SMS_LBIST_CTRL_DC_DEF_PROXY — Clock delay after scan_enable switching
0xE004 CFG0_SMS_LBIST_PATCOUNT_PROXY
  [29:16] SMS_LBIST_PATCOUNT_STATIC_PC_DEF_PROXY — Number of stuck-at patterns to run
  [11:8] SMS_LBIST_PATCOUNT_SET_PC_DEF_PROXY — Number of set patterns to run
  [7:4] SMS_LBIST_PATCOUNT_RESET_PC_DEF_PROXY — Number of reset patterns to run
  [3:0] SMS_LBIST_PATCOUNT_SCAN_PC_DEF_PROXY — Number of chain test patterns to run
0xE008 CFG0_SMS_LBIST_SEED0_PROXY
  [31:0] SMS_LBIST_SEED0_PRPG_DEF_PROXY — Initial seed for PRPG (bits 31:0)
0xE00C CFG0_SMS_LBIST_SEED1_PROXY
  [20:0] SMS_LBIST_SEED1_PRPG_DEF_PROXY — Initial seed for PRPG (bits 52:32)
0xE010 CFG0_SMS_LBIST_SPARE0_PROXY
  [31:0] SMS_LBIST_SPARE0_SPARE0_PROXY — LBIST spare bits
0xE014 CFG0_SMS_LBIST_SPARE1_PROXY
  [31:0] SMS_LBIST_SPARE1_SPARE1_PROXY — LBIST spare bits
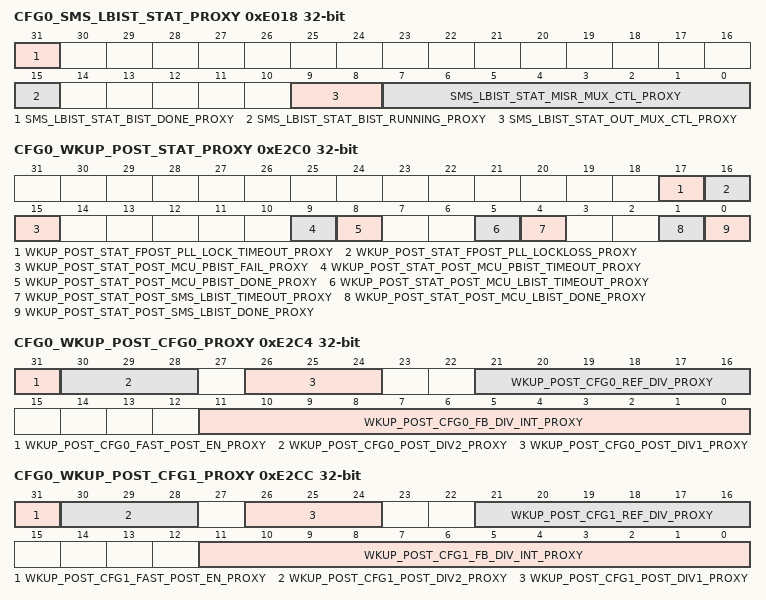
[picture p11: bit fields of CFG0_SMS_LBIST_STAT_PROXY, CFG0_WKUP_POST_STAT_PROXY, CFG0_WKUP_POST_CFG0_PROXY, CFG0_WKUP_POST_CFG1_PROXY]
0xE018 CFG0_SMS_LBIST_STAT_PROXY access per field
  [31] SMS_LBIST_STAT_BIST_DONE_PROXY ro — LBIST is done
  [15] SMS_LBIST_STAT_BIST_RUNNING_PROXY ro — LBIST is running
  [9:8] SMS_LBIST_STAT_OUT_MUX_CTL_PROXY rw — Selects source of LBIST output 00 - LBIST IP PID value 01 - LBIST CTRL ID value 1x - MISR value
  [7:0] SMS_LBIST_STAT_MISR_MUX_CTL_PROXY rw — Selects block of 32 MISR bits to read. A value of 0 selects a compacted 32-bit version of the full MISR. A value of 1-32 select a 32-bit segment of the MISR.
0xE01C CFG0_SMS_LBIST_MISR_PROXY ro
  [31:0] SMS_LBIST_MISR_MISR_RESULT_PROXY — 32-bits of MISR value selected by misr_mux_ctl
0xE280 CFG0_SMS_LBIST_SIG_PROXY ro
  [31:0] SMS_LBIST_SIG_MISR_SIG_PROXY — MISR signature
0xE2C0 CFG0_WKUP_POST_STAT_PROXY ro
  [17] WKUP_POST_STAT_FPOST_PLL_LOCK_TIMEOUT_PROXY — Indicates PLL lock timeout for Fast POST mode operation. 0 - PLLs locked, Fast POST mode was entered 1 - PLLs lock timeout occurred. Slow speed POST was performed
  [16] WKUP_POST_STAT_FPOST_PLL_LOCKLOSS_PROXY — Indicates if PLL lock was lost during POST 0 - No PLL lock loss. Fast POST was executed 1 - PLL lock was lost. POST was terminated
  [15] WKUP_POST_STAT_POST_MCU_PBIST_FAIL_PROXY — MCU PBIST failed
  [9] WKUP_POST_STAT_POST_MCU_PBIST_TIMEOUT_PROXY — MCU PBIST timed out
  [8] WKUP_POST_STAT_POST_MCU_PBIST_DONE_PROXY — MCU PBIST done
  [5] WKUP_POST_STAT_POST_MCU_LBIST_TIMEOUT_PROXY — MCU LBIST timed out
  [4] WKUP_POST_STAT_POST_SMS_LBIST_TIMEOUT_PROXY — SMS LBIST timed out
  [1] WKUP_POST_STAT_POST_MCU_LBIST_DONE_PROXY — MCU LBIST done
  [0] WKUP_POST_STAT_POST_SMS_LBIST_DONE_PROXY — SMS LBIST done
0xE2C4 CFG0_WKUP_POST_CFG0_PROXY ro
  [31] WKUP_POST_CFG0_FAST_POST_EN_PROXY — Enable Fast POST mode
  [30:28] WKUP_POST_CFG0_POST_DIV2_PROXY — Fast POST PLL secondary post-divider value
  [26:24] WKUP_POST_CFG0_POST_DIV1_PROXY — Fast POST PLL primary post-divider value
  [21:16] WKUP_POST_CFG0_REF_DIV_PROXY — Fast POST PLL reference clock pre-divider value
  [11:0] WKUP_POST_CFG0_FB_DIV_INT_PROXY — Fast POST PLL feedback divider (integer portion) value
0xE2CC CFG0_WKUP_POST_CFG1_PROXY ro
  [31] WKUP_POST_CFG1_FAST_POST_EN_PROXY — Enable Fast POST mode
  [30:28] WKUP_POST_CFG1_POST_DIV2_PROXY — Fast POST PLL secondary post-divider value
  [26:24] WKUP_POST_CFG1_POST_DIV1_PROXY — Fast POST PLL primary post-divider value
  [21:16] WKUP_POST_CFG1_REF_DIV_PROXY — Fast POST PLL reference clock pre-divider value
  [11:0] WKUP_POST_CFG1_FB_DIV_INT_PROXY — Fast POST PLL feedback divider (integer portion) value
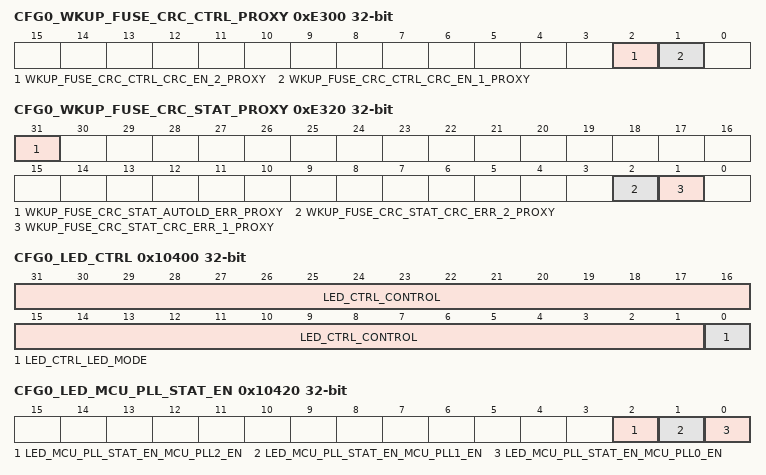
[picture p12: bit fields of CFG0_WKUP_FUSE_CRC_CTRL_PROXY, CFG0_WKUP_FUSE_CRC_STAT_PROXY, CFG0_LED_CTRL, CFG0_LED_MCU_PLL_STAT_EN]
0xE300 CFG0_WKUP_FUSE_CRC_CTRL_PROXY
  [2] WKUP_FUSE_CRC_CTRL_CRC_EN_2_PROXY — Enable eFuse CRC error output for chain 2
  [1] WKUP_FUSE_CRC_CTRL_CRC_EN_1_PROXY — Enable eFuse CRC error output for chain 1
0xE304 CFG0_WKUP_CHAIN1_CRC_FUSE_PROXY ro
  [31:0] WKUP_CHAIN1_CRC_FUSE_CRC_PROXY — Stored chain CRC
0xE308 CFG0_WKUP_CHAIN2_CRC_FUSE_PROXY ro
  [31:0] WKUP_CHAIN2_CRC_FUSE_CRC_PROXY — Stored chain CRC
0xE320 CFG0_WKUP_FUSE_CRC_STAT_PROXY ro
  [31] WKUP_FUSE_CRC_STAT_AUTOLD_ERR_PROXY — Indicates eFuse autoload or programmation error on any chain
  [2] WKUP_FUSE_CRC_STAT_CRC_ERR_2_PROXY — Indicates eFuse CRC error on chain 2
  [1] WKUP_FUSE_CRC_STAT_CRC_ERR_1_PROXY — Indicates eFuse CRC error on chain 1
0xE324 CFG0_WKUP_CHAIN1_CRC_CALC_PROXY ro
  [31:0] WKUP_CHAIN1_CRC_CALC_CRC_PROXY — Calculated chain CRC
0xE328 CFG0_WKUP_CHAIN2_CRC_CALC_PROXY ro
  [31:0] WKUP_CHAIN2_CRC_CALC_CRC_PROXY — Calculated chain CRC
{0xF100+4i} CFG0_CLAIMREG_P3_R{i} (i=0..6)
  [31:0] CLAIMREG_P3_R{i} — Claim bits for Partition 3
{0x10000+4i} CFG0_DV_REG{i} (i=0..63)
  [31:0] DV_REG{i}_BIT — Defined by DV usage
{0x10200+4i} CFG0_DV_REG{i}_SET access not given (i=0..31)
  [31:0] DV_REG{i}_SET_BIT — Defined by DV usage (access R/W1TS)
{0x10300+4i} CFG0_DV_REG{i}_CLR access not given (i=0..31)
  [31:0] DV_REG{i}_CLR_BIT — Defined by DV usage (access R/W1TC)
0x10400 CFG0_LED_CTRL access per field
  [31:1] LED_CTRL_CONTROL rw — Test control
  [0] LED_CTRL_LED_MODE ro — LED mode from decoded enable key
0x10408 CFG0_LED_ENABLE
  [31:0] LED_ENABLE_ENABLE_KEY — LED mode entry key 32'h204C4544 - Set PADCONFIG registers to LED mode values others - PADCONFIG registers retain programmed values
0x10420 CFG0_LED_MCU_PLL_STAT_EN
  [2] LED_MCU_PLL_STAT_EN_MCU_PLL2_EN — Enable MCU_PLL2 lockloss in status generation
  [1] LED_MCU_PLL_STAT_EN_MCU_PLL1_EN — Enable MCU_PLL1 lockloss in status generation
  [0] LED_MCU_PLL_STAT_EN_MCU_PLL0_EN — Enable MCU_PLL0 lockloss in status generation
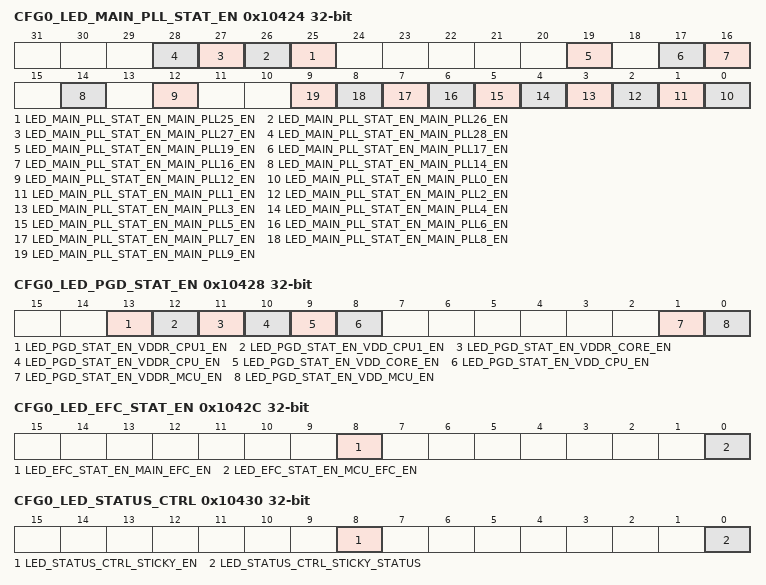
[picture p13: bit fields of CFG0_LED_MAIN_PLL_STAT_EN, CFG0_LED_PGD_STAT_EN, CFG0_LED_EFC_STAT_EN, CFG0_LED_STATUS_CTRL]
0x10424 CFG0_LED_MAIN_PLL_STAT_EN
  [n] LED_MAIN_PLL_STAT_EN_MAIN_PLL{n}_EN (n=25..28) — Enable MAIN_PLL{n} lockloss in status generation
  [19] LED_MAIN_PLL_STAT_EN_MAIN_PLL19_EN — Enable MAIN_PLL19 lockloss in status generation
  [17] LED_MAIN_PLL_STAT_EN_MAIN_PLL17_EN — Enable MAIN_PLL17 lockloss in status generation
  [16] LED_MAIN_PLL_STAT_EN_MAIN_PLL16_EN — Enable MAIN_PLL16 lockloss in status generation
  [14] LED_MAIN_PLL_STAT_EN_MAIN_PLL14_EN — Enable MAIN_PLL14 lockloss in status generation
  [12] LED_MAIN_PLL_STAT_EN_MAIN_PLL12_EN — Enable MAIN_PLL12 lockloss in status generation
  [n] LED_MAIN_PLL_STAT_EN_MAIN_PLL{n}_EN (n=0..9) — Enable MAIN_PLL{n} lockloss in status generation
0x10428 CFG0_LED_PGD_STAT_EN
  [13] LED_PGD_STAT_EN_VDDR_CPU1_EN — Enable vddr_cpu1 PGD in status generation
  [12] LED_PGD_STAT_EN_VDD_CPU1_EN — Enable vdd_cpu1 PGD in status generation
  [11] LED_PGD_STAT_EN_VDDR_CORE_EN — Enable vddr_core PGD in status generation
  [10] LED_PGD_STAT_EN_VDDR_CPU_EN — Enable vddr_cpu PGD in status generation
  [9] LED_PGD_STAT_EN_VDD_CORE_EN — Enable vdd_core PGD in status generation
  [8] LED_PGD_STAT_EN_VDD_CPU_EN — Enable vdd_cpu PGD in status generation
  [1] LED_PGD_STAT_EN_VDDR_MCU_EN — Enable vddr_mcu PGD in status generation
  [0] LED_PGD_STAT_EN_VDD_MCU_EN — Enable vdd_mcu PGD in status generation
0x1042C CFG0_LED_EFC_STAT_EN
  [8] LED_EFC_STAT_EN_MAIN_EFC_EN — Enable MAIN eFuse Ctrl PGD in status generation
  [0] LED_EFC_STAT_EN_MCU_EFC_EN — Enable MCU eFuse Ctrl PGD in status generation
0x10430 CFG0_LED_STATUS_CTRL
  [8] LED_STATUS_CTRL_STICKY_EN — Sticky status enable. Selects which version of status to output on the pin. 0 - Use real-time status signal 1 - Use sticky status signal
  [0] LED_STATUS_CTRL_STICKY_STATUS — Sticky status bit. This bit captures the falling edge of the status signal
{0x10480+4i} CFG0_SIM_CFG{i} (i=0..7)
  [31:0] SIM_CFG{i}_CFG_INFO — Model configuration info. Bit usage is determined by AVV team.
0x10500 CFG0_WKUP_MRGN_MODE0
  [11:0] WKUP_MRGN_MODE0_HS2PARF_MEM_MRGN_ASST — DFT memory margin control Bits 0-3 - dft_mem_margin Bits 4-5 - dft_mem_ra Bits 6-8 - dft_mem_wa Bits 9-11 - dft_wpulse
0x10504 CFG0_WKUP_MRGN_MODE1
  [11:0] WKUP_MRGN_MODE1_HDDP_MEM_MRGN_ASST — DFT memory margin control Bits 0-3 - dft_mem_margin Bits 4-5 - dft_mem_ra Bits 6-8 - dft_mem_wa Bits 9-11 - dft_wpulse
0x10508 CFG0_WKUP_MRGN_MODE2
  [11:0] WKUP_MRGN_MODE2_EHDSP_MEM_MRGN_ASST — DFT memory margin control Bits 0-3 - dft_mem_margin Bits 4-5 - dft_mem_ra Bits 6-8 - dft_mem_wa Bits 9-11 - dft_wpulse
0x1050C CFG0_WKUP_MRGN_MODE3
  [11:0] WKUP_MRGN_MODE3_HD2PRF_MEM_MRGN_ASST — DFT memory margin control Bits 0-3 - dft_mem_margin Bits 4-5 - dft_mem_ra Bits 6-8 - dft_mem_wa Bits 9-11 - dft_wpulse
0x10510 CFG0_WKUP_MRGN_MODE4
  [11:0] WKUP_MRGN_MODE4_UHD2PRF_MEM_MRGN_ASST — DFT memory margin control Bits 0-3 - dft_mem_margin Bits 4-5 - dft_mem_ra Bits 6-8 - dft_mem_wa Bits 9-11 - dft_wpulse
0x10514 CFG0_WKUP_MRGN_MODE5
  [11:0] WKUP_MRGN_MODE5_ROM_MEM_MRGN_ASST — DFT memory margin control Bits 0-3 - dft_mem_margin Bits 4-5 - dft_mem_ra Bits 6-8 - dft_mem_wa Bits 9-11 - dft_wpulse
0x10518 CFG0_WKUP_MRGN_MODE6
  [11:0] WKUP_MRGN_MODE6_HDSP_MEM_MRGN_ASST — DFT memory margin control Bits 0-3 - dft_mem_margin Bits 4-5 - dft_mem_ra Bits 6-8 - dft_mem_wa Bits 9-11 - dft_wpulse
0x1051C CFG0_WKUP_MRGN_MODE7
  [11:0] WKUP_MRGN_MODE7_HSSP_MEM_MRGN_ASST — DFT memory margin control Bits 0-3 - dft_mem_margin Bits 4-5 - dft_mem_ra Bits 6-8 - dft_mem_wa Bits 9-11 - dft_wpulse
0x10520 CFG0_WKUP_MRGN_MODE8
  [11:0] WKUP_MRGN_MODE8_HD1PRF_MEM_MRGN_ASST — DFT memory margin control Bits 0-3 - dft_mem_margin Bits 4-5 - dft_mem_ra Bits 6-8 - dft_mem_wa Bits 9-11 - dft_wpulse
0x10524 CFG0_WKUP_MRGN_MODE9
  [11:0] WKUP_MRGN_MODE9_HS1PRF_MEM_MRGN_ASST — DFT memory margin control Bits 0-3 - dft_mem_margin Bits 4-5 - dft_mem_ra Bits 6-8 - dft_mem_wa Bits 9-11 - dft_wpulse
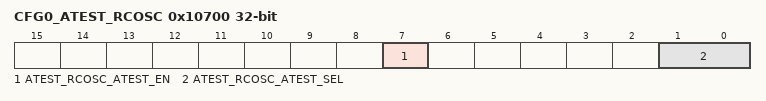
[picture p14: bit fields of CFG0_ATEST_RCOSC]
0x10700 CFG0_ATEST_RCOSC
  [7] ATEST_RCOSC_ATEST_EN — Test enable 1'b0 - Disable (atestout is floating) 1'b1 - Enable (see atest_test)
  [1:0] ATEST_RCOSC_ATEST_SEL — Test select When atest_en = 1 2'b0x - Hi-Z (Test 3) 2'b10 - Bias current (Test 1) 2'b11 - VREF (Test 2)
0x10720 CFG0_ATEST_HFOSC0
  [0] ATEST_HFOSC0_TEST_EN_C — Test enable 1'b0 - Output test current disabled 1'b1 - Test current enabled
0x10724 CFG0_ATEST_HFOSC1
  [0] ATEST_HFOSC1_TEST_EN_C — Test enable 1'b0 - Output test current disabled 1'b1 - Test current enabled
